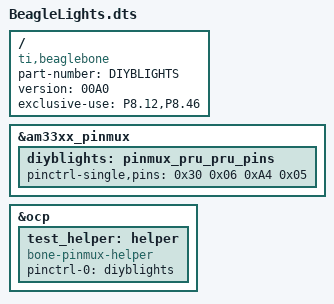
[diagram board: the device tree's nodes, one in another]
/*
    * Copyright (C) 2012 Texas Instruments Incorporated - http://www.ti.com/
    *
    * This program is free software; you can redistribute it and/or modify
    * it under the terms of the GNU General Purpose License Version 2 as
    * published by the Free Software Foundation
    *
    * Original from: github.com/jadonk/validation-scripts/blob/master/test-capemgr/
    *
    * Modified by Derek Molloy for the example on www.derekmolloy.ie
    * that maps GPIO pins for the example
    * Modified again by Charles Kerr for his project
    */

    /dts-v1/;
    /plugin/;

    /{
        compatible = "ti,beaglebone", "ti,beaglebone-black";
        part-number = "DIYBLIGHTS";
        version = "00A0";
        exclusive-use = "P8.12,P8.46";
        fragment@0 {
            target = <&am33xx_pinmux>;
            __overlay__ {
                diyblights: pinmux_pru_pru_pins {
                    pinctrl-single,pins = <
                        0x30 0x06  /* P8_12 GPIO:44 $PINS:12 MODE 6 -pru0 R30_14 */
                        0xA4 0x05  /* P8_46 GPIO:71 $PINS:41 MODE 5 - pru1 R30_1 */
                    >;
                };
            };
        };

        fragment@1 {
            target = <&ocp>;
            __overlay__ {
                test_helper: helper {
                    compatible = "bone-pinmux-helper";
                    pinctrl-names = "default";
                    pinctrl-0 = <&diyblights>;
                    status = "okay";
                };
            };
        };
    };
